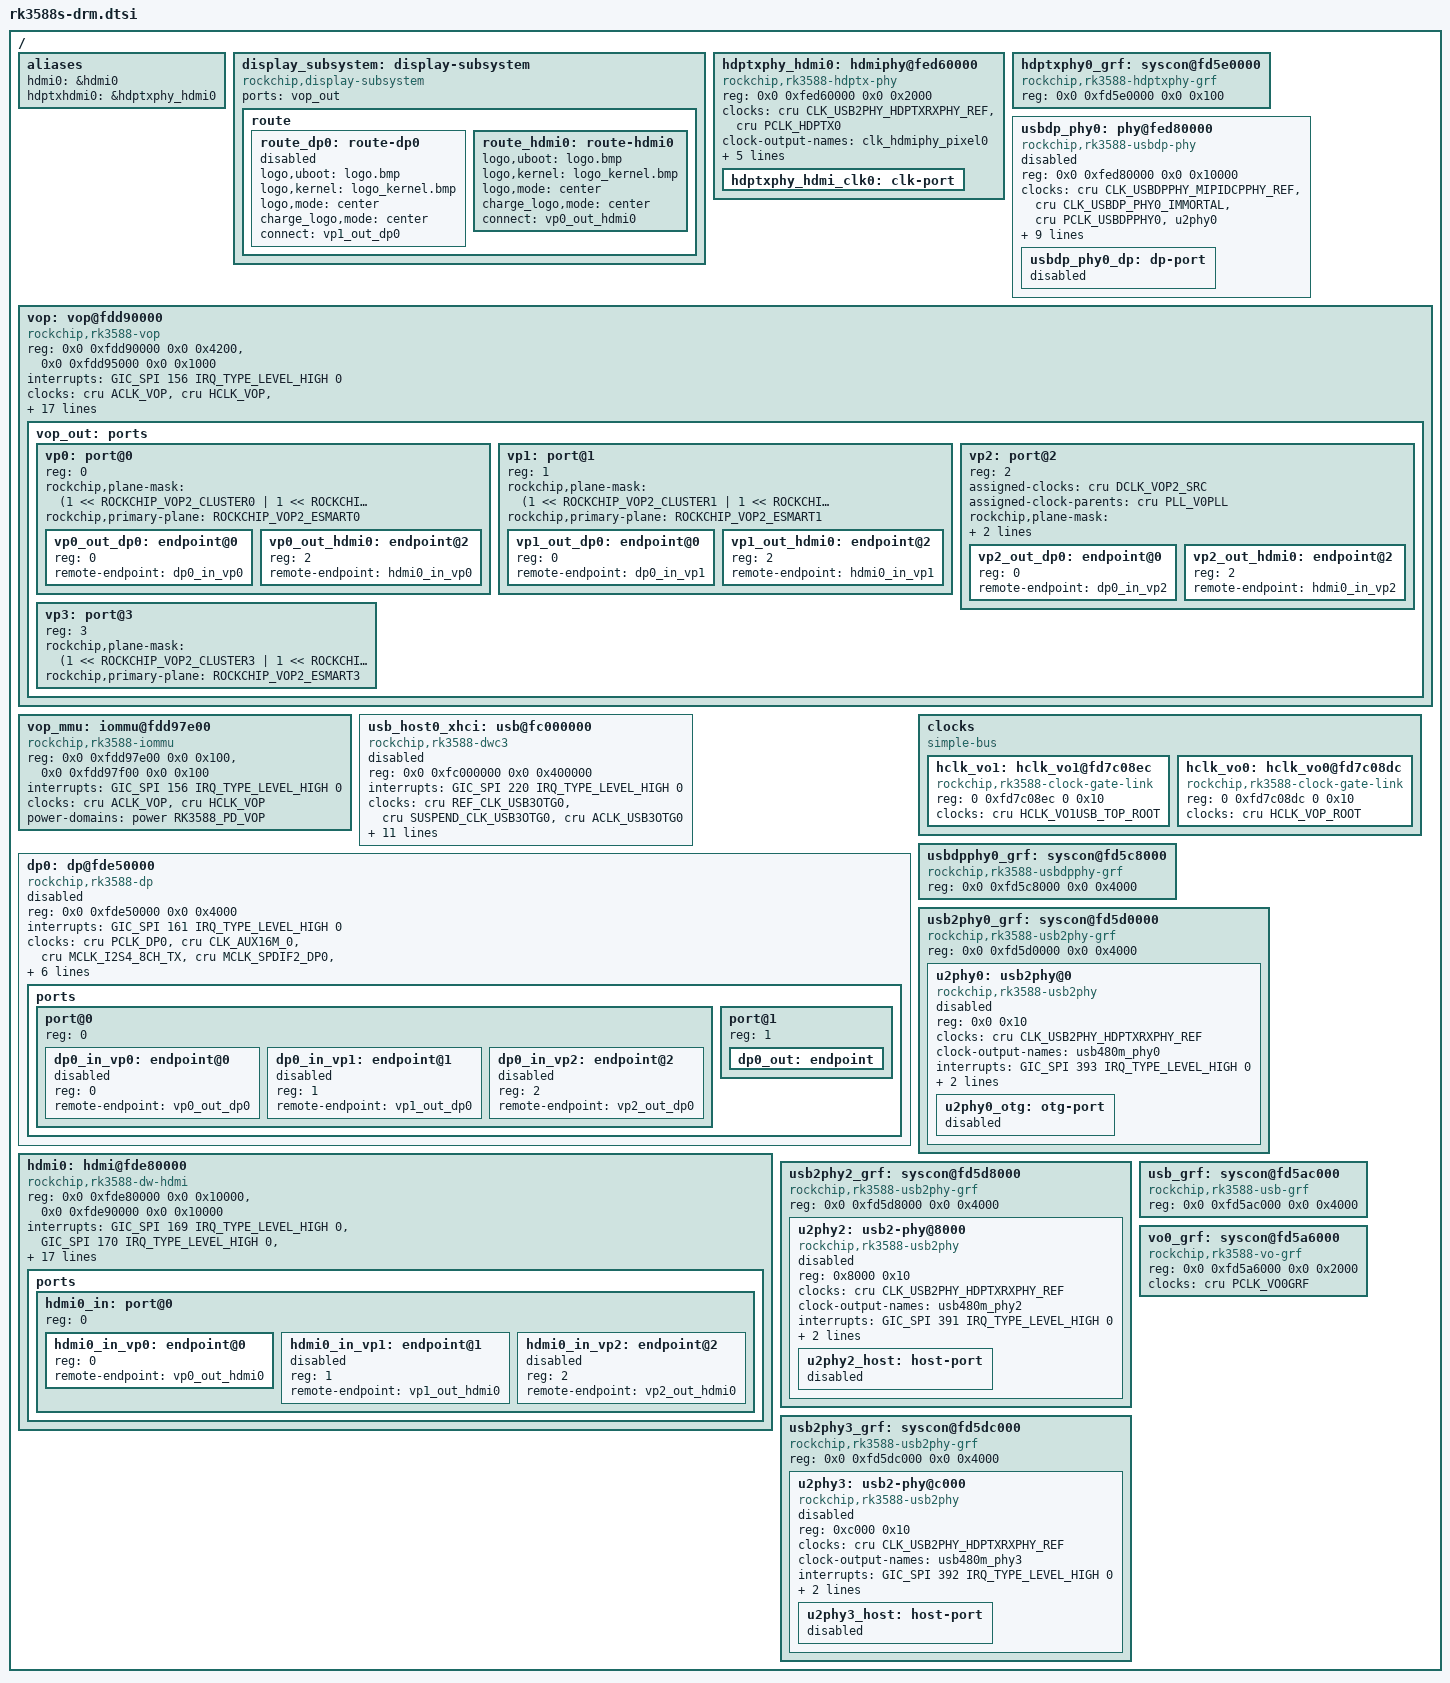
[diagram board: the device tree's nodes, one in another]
#include <dt-bindings/display/rockchip_vop.h>

/ {
	aliases {
		hdmi0 = &hdmi0;
		hdptxhdmi0 = &hdptxphy_hdmi0;
	};
	
	display_subsystem: display-subsystem {
		compatible = "rockchip,display-subsystem";
		ports = <&vop_out>;
		
		route {
			route_dp0: route-dp0 {
				status = "disabled";
				logo,uboot = "logo.bmp";
				logo,kernel = "logo_kernel.bmp";
				logo,mode = "center";
				charge_logo,mode = "center";
				connect = <&vp1_out_dp0>;
			};
			
			route_hdmi0: route-hdmi0 {
				status = "disabled";
				logo,uboot = "logo.bmp";
				logo,kernel = "logo_kernel.bmp";
				logo,mode = "center";
				charge_logo,mode = "center";
				connect = <&vp0_out_hdmi0>;
			};
		};
	};
	
	hdptxphy_hdmi0: hdmiphy@fed60000 {
		compatible = "rockchip,rk3588-hdptx-phy";
		reg = <0x0 0xfed60000 0x0 0x2000>;
		clocks = <&cru CLK_USB2PHY_HDPTXRXPHY_REF>, <&cru PCLK_HDPTX0>;
		clock-names = "ref", "apb";
		clock-output-names = "clk_hdmiphy_pixel0";
		#clock-cells = <0>;
		#phy-cells = <0>;
		resets = <&cru SRST_HDPTX0>, <&cru SRST_P_HDPTX0>,
		<&cru SRST_HDPTX0_INIT>, <&cru SRST_HDPTX0_CMN>,
		<&cru SRST_HDPTX0_LANE>, <&cru SRST_HDPTX0_ROPLL>,
		<&cru SRST_HDPTX0_LCPLL>;
		reset-names = "phy", "apb", "init", "cmn", "lane", "ropll",
		"lcpll";
		rockchip,grf = <&hdptxphy0_grf>;
		status = "disabled";
		
		hdptxphy_hdmi_clk0: clk-port {
			#clock-cells = <0>;
			status = "okay";
		};
	};
	
	hdptxphy0_grf: syscon@fd5e0000 {
		compatible = "rockchip,rk3588-hdptxphy-grf", "syscon";
		reg = <0x0 0xfd5e0000 0x0 0x100>;
	};
	
	usbdp_phy0: phy@fed80000 {
		compatible = "rockchip,rk3588-usbdp-phy";
		reg = <0x0 0xfed80000 0x0 0x10000>;
		#phy-cells = <1>;
		clocks = <&cru CLK_USBDPPHY_MIPIDCPPHY_REF>,
		<&cru CLK_USBDP_PHY0_IMMORTAL>,
		<&cru PCLK_USBDPPHY0>,
		<&u2phy0>;
		clock-names = "refclk", "immortal", "pclk", "utmi";
		resets = <&cru SRST_USBDP_COMBO_PHY0_INIT>,
		<&cru SRST_USBDP_COMBO_PHY0_CMN>,
		<&cru SRST_USBDP_COMBO_PHY0_LANE>,
		<&cru SRST_USBDP_COMBO_PHY0_PCS>,
		<&cru SRST_P_USBDPPHY0>;
		reset-names = "init", "cmn", "lane", "pcs_apb", "pma_apb";
		rockchip,u2phy-grf = <&usb2phy0_grf>;
		rockchip,usb-grf = <&usb_grf>;
		rockchip,usbdpphy-grf = <&usbdpphy0_grf>;
		rockchip,vo-grf = <&vo0_grf>;
		status = "disabled";
		
		usbdp_phy0_dp: dp-port {
			#phy-cells = <0>;
			status = "disabled";
		};
	};
	
	// dfi: dfi@fe060000 {
	// 	reg = <0x00 0xfe060000 0x00 0x10000>;
	// 	compatible = "rockchip,rk3588-dfi";
	// 	interrupts = <GIC_SPI 28 IRQ_TYPE_LEVEL_HIGH 0>,
	// 	<GIC_SPI 38 IRQ_TYPE_LEVEL_HIGH 0>,
	// 	<GIC_SPI 48 IRQ_TYPE_LEVEL_HIGH 0>,
	// 	<GIC_SPI 58 IRQ_TYPE_LEVEL_HIGH 0>;
	// 	rockchip,pmu = <&pmu1grf>;
	// };
	
	vop: vop@fdd90000 {
		compatible = "rockchip,rk3588-vop";
		reg = <0x0 0xfdd90000 0x0 0x4200>, <0x0 0xfdd95000 0x0 0x1000>;
		reg-names = "regs", "gamma_lut";
		interrupts = <GIC_SPI 156 IRQ_TYPE_LEVEL_HIGH 0>;
		clocks = <&cru ACLK_VOP>,
		<&cru HCLK_VOP>,
		<&cru DCLK_VOP0>,
		<&cru DCLK_VOP1>,
		<&cru DCLK_VOP2>,
		<&cru DCLK_VOP3>,
		<&cru PCLK_VOP_ROOT>,
		<&cru DCLK_VOP0_SRC>,
		<&cru DCLK_VOP1_SRC>,
		<&cru DCLK_VOP2_SRC>;
		clock-names = "aclk_vop",
		"hclk_vop",
		"dclk_vp0",
		"dclk_vp1",
		"dclk_vp2",
		"dclk_vp3",
		"pclk_vop",
		"dclk_src_vp0",
		"dclk_src_vp1",
		"dclk_src_vp2";
		assigned-clocks = <&cru ACLK_VOP>;
		assigned-clock-rates = <750000000>;
		resets = <&cru SRST_A_VOP>,
		<&cru SRST_H_VOP>,
		<&cru SRST_D_VOP0>,
		<&cru SRST_D_VOP1>,
		<&cru SRST_D_VOP2>,
		<&cru SRST_D_VOP3>;
		reset-names = "axi",
		"ahb",
		"dclk_vp0",
		"dclk_vp1",
		"dclk_vp2",
		"dclk_vp3";
		rockchip,aclk-normal-mode-rates = <500000000>;
		rockchip,aclk-advanced-mode-rates = <750000000>;
		iommus = <&vop_mmu>;
		power-domains = <&power RK3588_PD_VOP>;
		rockchip,grf = <&sys_grf>;
		rockchip,vop-grf = <&vop_grf>;
		rockchip,vo1-grf = <&vo1_grf>;
		rockchip,pmu = <&pmu>;
		status = "disabled";
		
		vop_out: ports {
			#address-cells = <1>;
			#size-cells = <0>;
			
			vp0: port@0 {
				#address-cells = <1>;
				#size-cells = <0>;
				reg = <0>;
				
				vp0_out_dp0: endpoint@0 {
					reg = <0>;
					remote-endpoint = <&dp0_in_vp0>;
				};
				
				vp0_out_hdmi0: endpoint@2 {
					reg = <2>;
					remote-endpoint = <&hdmi0_in_vp0>;
				};
			};
			
			vp1: port@1 {
				#address-cells = <1>;
				#size-cells = <0>;
				reg = <1>;
				
				vp1_out_dp0: endpoint@0 {
					reg = <0>;
					remote-endpoint = <&dp0_in_vp1>;
				};
				
				vp1_out_hdmi0: endpoint@2 {
					reg = <2>;
					remote-endpoint = <&hdmi0_in_vp1>;
				};
			};
			
			vp2: port@2 {
				#address-cells = <1>;
				#size-cells = <0>;
				reg = <2>;
				
				assigned-clocks = <&cru DCLK_VOP2_SRC>;
				assigned-clock-parents = <&cru PLL_V0PLL>;
				
				vp2_out_dp0: endpoint@0 {
					reg = <0>;
					remote-endpoint = <&dp0_in_vp2>;
				};
				
				vp2_out_hdmi0: endpoint@2 {
					reg = <2>;
					remote-endpoint = <&hdmi0_in_vp2>;
				};
			};
			
			vp3: port@3 {
				#address-cells = <1>;
				#size-cells = <0>;
				reg = <3>;
			};
		};
	};
	
	vop_mmu: iommu@fdd97e00 {
		compatible = "rockchip,rk3588-iommu", "rockchip,rk3568-iommu";
		reg = <0x0 0xfdd97e00 0x0 0x100>, <0x0 0xfdd97f00 0x0 0x100>;
		interrupts = <GIC_SPI 156 IRQ_TYPE_LEVEL_HIGH 0>;
		clocks = <&cru ACLK_VOP>, <&cru HCLK_VOP>;
		clock-names = "aclk", "iface";
		#iommu-cells = <0>;
		power-domains = <&power RK3588_PD_VOP>;
		status = "disabled";
	};
	
	usb_host0_xhci: usb@fc000000 {
		compatible = "rockchip,rk3588-dwc3", "snps,dwc3";
		reg = <0x0 0xfc000000 0x0 0x400000>;
		interrupts = <GIC_SPI 220 IRQ_TYPE_LEVEL_HIGH 0>;
		clocks = <&cru REF_CLK_USB3OTG0>, <&cru SUSPEND_CLK_USB3OTG0>,
		<&cru ACLK_USB3OTG0>;
		clock-names = "ref_clk", "suspend_clk", "bus_clk";
		dr_mode = "otg";
		phys = <&u2phy0_otg>, <&usbdp_phy0 PHY_TYPE_USB3>;
		phy-names = "usb2-phy", "usb3-phy";
		phy_type = "utmi_wide";
		power-domains = <&power RK3588_PD_USB>;
		resets = <&cru SRST_A_USB3OTG0>;
		snps,dis_enblslpm_quirk;
		snps,dis-u1-entry-quirk;
		snps,dis-u2-entry-quirk;
		snps,dis-u2-freeclk-exists-quirk;
		snps,dis-del-phy-power-chg-quirk;
		snps,dis-tx-ipgap-linecheck-quirk;
		status = "disabled";
	};
	
	dp0: dp@fde50000 {
		compatible = "rockchip,rk3588-dp";
		reg = <0x0 0xfde50000 0x0 0x4000>;
		interrupts = <GIC_SPI 161 IRQ_TYPE_LEVEL_HIGH 0>;
		clocks = <&cru PCLK_DP0>, <&cru CLK_AUX16M_0>,
		<&cru MCLK_I2S4_8CH_TX>, <&cru MCLK_SPDIF2_DP0>,
		<&hclk_vo0>, <&cru CLK_DP0>;
		clock-names = "apb", "aux", "i2s", "spdif", "hclk", "hdcp";
		assigned-clocks = <&cru CLK_AUX16M_0>;
		assigned-clock-rates = <16000000>;
		resets = <&cru SRST_DP0>;
		phys = <&usbdp_phy0_dp>;
		power-domains = <&power RK3588_PD_VO0>;
		#sound-dai-cells = <1>;
		status = "disabled";
		
		ports {
			#address-cells = <1>;
			#size-cells = <0>;
			
			port@0 {
				reg = <0>;
				#address-cells = <1>;
				#size-cells = <0>;
				
				dp0_in_vp0: endpoint@0 {
					reg = <0>;
					remote-endpoint = <&vp0_out_dp0>;
					status = "disabled";
				};
				
				dp0_in_vp1: endpoint@1 {
					reg = <1>;
					remote-endpoint = <&vp1_out_dp0>;
					status = "disabled";
				};
				
				dp0_in_vp2: endpoint@2 {
					reg = <2>;
					remote-endpoint = <&vp2_out_dp0>;
					status = "disabled";
				};
			};
			
			port@1 {
				reg = <1>;
				
			dp0_out: endpoint { };
			};
		};
	};
	
	hdmi0: hdmi@fde80000 {
		compatible = "rockchip,rk3588-dw-hdmi";
		reg = <0x0 0xfde80000 0x0 0x10000>, <0x0 0xfde90000 0x0 0x10000>;
		interrupts = <GIC_SPI 169 IRQ_TYPE_LEVEL_HIGH 0>,
		<GIC_SPI 170 IRQ_TYPE_LEVEL_HIGH 0>,
		<GIC_SPI 171 IRQ_TYPE_LEVEL_HIGH 0>,
		<GIC_SPI 172 IRQ_TYPE_LEVEL_HIGH 0>,
		<GIC_SPI 360 IRQ_TYPE_LEVEL_HIGH 0>;
		clocks = <&cru PCLK_HDMITX0>,
		<&cru CLK_HDMIHDP0>,
		<&cru CLK_HDMITX0_EARC>,
		<&cru CLK_HDMITX0_REF>,
		<&cru MCLK_I2S5_8CH_TX>,
		<&cru DCLK_VOP0>,
		<&cru DCLK_VOP1>,
		<&cru DCLK_VOP2>,
		<&cru DCLK_VOP3>,
		<&hclk_vo1>,
		<&hdptxphy_hdmi_clk0>;
		clock-names = "pclk",
		"hpd",
		"earc",
		"hdmitx_ref",
		"aud",
		"dclk_vp0",
		"dclk_vp1",
		"dclk_vp2",
		"dclk_vp3",
		"hclk_vo1",
		"link_clk";
		resets = <&cru SRST_HDMITX0_REF>, <&cru SRST_HDMIHDP0>;
		reset-names = "ref", "hdp";
		power-domains = <&power RK3588_PD_VO1>;
		pinctrl-names = "default";
		pinctrl-0 = <&hdmim0_tx0_cec &hdmim0_tx0_hpd &hdmim0_tx0_scl &hdmim0_tx0_sda>;
		reg-io-width = <4>;
		rockchip,grf = <&sys_grf>;
		rockchip,vo1_grf = <&vo1_grf>;
		phys = <&hdptxphy_hdmi0>;
		phy-names = "hdmi";
		#sound-dai-cells = <0>;
		status = "disabled";
		
		ports {
			#address-cells = <1>;
			#size-cells = <0>;
			
			hdmi0_in: port@0 {
				reg = <0>;
				#address-cells = <1>;
				#size-cells = <0>;
				
				hdmi0_in_vp0: endpoint@0 {
					reg = <0>;
					remote-endpoint = <&vp0_out_hdmi0>;
					status = "disabled";
				};
				
				hdmi0_in_vp1: endpoint@1 {
					reg = <1>;
					remote-endpoint = <&vp1_out_hdmi0>;
					status = "disabled";
				};
				
				hdmi0_in_vp2: endpoint@2 {
					reg = <2>;
					remote-endpoint = <&vp2_out_hdmi0>;
					status = "disabled";
				};
			};
		};
	};
	
	clocks {
		compatible = "simple-bus";
		#address-cells = <2>;
		#size-cells = <2>;
		ranges;
		hclk_vo1: hclk_vo1@fd7c08ec {
			compatible = "rockchip,rk3588-clock-gate-link";
			reg = <0 0xfd7c08ec 0 0x10>;
			clock-names = "link";
			clocks = <&cru HCLK_VO1USB_TOP_ROOT>;
			#power-domain-cells = <1>;
			#clock-cells = <0>;
		};
		hclk_vo0: hclk_vo0@fd7c08dc {
			compatible = "rockchip,rk3588-clock-gate-link";
			reg = <0 0xfd7c08dc 0 0x10>;
			clock-names = "link";
			clocks = <&cru HCLK_VOP_ROOT>;
			#power-domain-cells = <1>;
			#clock-cells = <0>;
		};
	};
	
	usbdpphy0_grf: syscon@fd5c8000 {
		compatible = "rockchip,rk3588-usbdpphy-grf", "syscon";
		reg = <0x0 0xfd5c8000 0x0 0x4000>;
	};
	
	usb2phy0_grf: syscon@fd5d0000 {
		compatible = "rockchip,rk3588-usb2phy-grf", "syscon", "simple-mfd";
		reg = <0x0 0xfd5d0000 0x0 0x4000>;
		#address-cells = <1>;
		#size-cells = <1>;
		
		u2phy0: usb2phy@0 {
			compatible = "rockchip,rk3588-usb2phy";
			reg = <0x0 0x10>;
			#clock-cells = <0>;
			clocks = <&cru CLK_USB2PHY_HDPTXRXPHY_REF>;
			clock-names = "phyclk";
			clock-output-names = "usb480m_phy0";
			interrupts = <GIC_SPI 393 IRQ_TYPE_LEVEL_HIGH 0>;
			resets = <&cru SRST_OTGPHY_U3_0>, <&cru SRST_P_USB2PHY_U3_0_GRF0>;
			reset-names = "phy", "apb";
			status = "disabled";
			
			u2phy0_otg: otg-port {
				#phy-cells = <0>;
				status = "disabled";
			};
		};
	};
	
	usb2phy2_grf: syscon@fd5d8000 {
		compatible = "rockchip,rk3588-usb2phy-grf", "syscon", "simple-mfd";
		reg = <0x0 0xfd5d8000 0x0 0x4000>;
		#address-cells = <1>;
		#size-cells = <1>;
		
		u2phy2: usb2-phy@8000 {
			compatible = "rockchip,rk3588-usb2phy";
			reg = <0x8000 0x10>;
			#clock-cells = <0>;
			clocks = <&cru CLK_USB2PHY_HDPTXRXPHY_REF>;
			clock-names = "phyclk";
			clock-output-names = "usb480m_phy2";
			interrupts = <GIC_SPI 391 IRQ_TYPE_LEVEL_HIGH 0>;
			resets = <&cru SRST_OTGPHY_U2_0>, <&cru SRST_P_USB2PHY_U2_0_GRF0>;
			reset-names = "phy", "apb";
			status = "disabled";
			
			u2phy2_host: host-port {
				#phy-cells = <0>;
				status = "disabled";
			};
		};
	};
	
	usb2phy3_grf: syscon@fd5dc000 {
		compatible = "rockchip,rk3588-usb2phy-grf", "syscon", "simple-mfd";
		reg = <0x0 0xfd5dc000 0x0 0x4000>;
		#address-cells = <1>;
		#size-cells = <1>;
		
		u2phy3: usb2-phy@c000 {
			compatible = "rockchip,rk3588-usb2phy";
			reg = <0xc000 0x10>;
			#clock-cells = <0>;
			clocks = <&cru CLK_USB2PHY_HDPTXRXPHY_REF>;
			clock-names = "phyclk";
			clock-output-names = "usb480m_phy3";
			interrupts = <GIC_SPI 392 IRQ_TYPE_LEVEL_HIGH 0>;
			resets = <&cru SRST_OTGPHY_U2_1>, <&cru SRST_P_USB2PHY_U2_1_GRF0>;
			reset-names = "phy", "apb";
			status = "disabled";
			
			u2phy3_host: host-port {
				#phy-cells = <0>;
				status = "disabled";
			};
		};
	};
	
	usb_grf: syscon@fd5ac000 {
		compatible = "rockchip,rk3588-usb-grf", "syscon";
		reg = <0x0 0xfd5ac000 0x0 0x4000>;
	};
	
	vo0_grf: syscon@fd5a6000 {
		compatible = "rockchip,rk3588-vo-grf", "syscon";
		reg = <0x0 0xfd5a6000 0x0 0x2000>;
		clocks = <&cru PCLK_VO0GRF>;
	};
};


&vop {
	status = "okay";
};

&vop_mmu {
	status = "okay";
};

/* vp0 & vp1 splice for 8K output */
&vp0 {
	rockchip,plane-mask = <(1 << ROCKCHIP_VOP2_CLUSTER0 | 1 << ROCKCHIP_VOP2_ESMART0)>;
	rockchip,primary-plane = <ROCKCHIP_VOP2_ESMART0>;
	//  rockchip,primary-plane = <ROCKCHIP_VOP2_CLUSTER0>;
	//  cursor-win-id = <ROCKCHIP_VOP2_ESMART0>;
};

&vp1 {
	rockchip,plane-mask = <(1 << ROCKCHIP_VOP2_CLUSTER1 | 1 << ROCKCHIP_VOP2_ESMART1)>;
	rockchip,primary-plane = <ROCKCHIP_VOP2_ESMART1>;
	//  rockchip,primary-plane = <ROCKCHIP_VOP2_CLUSTER1>;
	//  cursor-win-id = <ROCKCHIP_VOP2_ESMART1>;
};

&vp2 {
	rockchip,plane-mask = <(1 << ROCKCHIP_VOP2_CLUSTER2 | 1 << ROCKCHIP_VOP2_ESMART2)>;
	rockchip,primary-plane = <ROCKCHIP_VOP2_ESMART2>;
	//  rockchip,primary-plane = <ROCKCHIP_VOP2_CLUSTER2>;
	//  cursor-win-id = <ROCKCHIP_VOP2_ESMART2>;
};

&vp3 {
	rockchip,plane-mask = <(1 << ROCKCHIP_VOP2_CLUSTER3 | 1 << ROCKCHIP_VOP2_ESMART3)>;
	rockchip,primary-plane = <ROCKCHIP_VOP2_ESMART3>;
	//  rockchip,primary-plane = <ROCKCHIP_VOP2_CLUSTER3>;
	//  cursor-win-id = <ROCKCHIP_VOP2_ESMART3>;
};

&hdptxphy_hdmi0 {
	status = "okay";
};

&hdmi0 {
	status = "okay";
};

&hdmi0_in_vp0 {
	status = "okay";
};

&route_hdmi0 {
	status = "okay";
};
